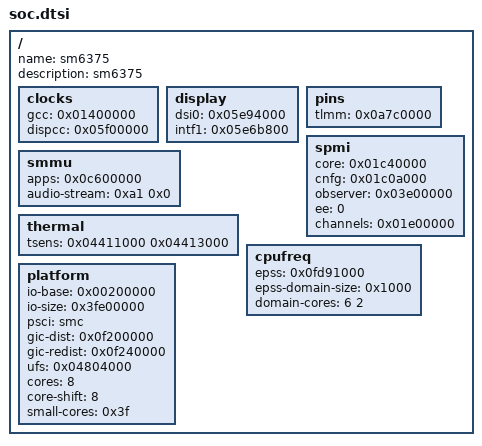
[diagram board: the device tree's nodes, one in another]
/dts-v1/;

// sm6375. Started by tools/boards.py new from malmo.dts.
// What every board with this SoC shares: where its blocks are (Documentation/porting.md).
/ {
	name = "sm6375";
	description = "sm6375";

	// The clocks the display block's registers need before they can be read: for a "dcs" backlight and
	// the feature "display-scan". The addresses are in the tree; the offsets are not -- they are in Linux's
	// clock drivers for the SoC (gcc-CODENAME.c, dispcc-CODENAME.c).
	clocks {
		gcc = <0x01400000>;             // clock-controller@100000 (qcom,CODENAME-gcc); the only key of this section
		                                // that the part drivers need
		// gcc-disp-ahb-cbcr = <0x...>; // TO FILL IN: gcc_disp_ahb_clk: its .halt_reg
		dispcc = <0x05f00000>;          // clock-controller@af00000 (qcom,CODENAME-dispcc)
		// dispcc-mdss-gdscr = <0x...>; // TO FILL IN: the display block's power switch (mdss_core_gdsc): its .gdscr
		// dispcc-mdss-ahb-cbcr = <0x...>; // TO FILL IN: disp_cc_mdss_ahb_clk
	};

	display {
		dsi0 = <0x05e94000>;            // the first DSI controller (cell-index 0), reg "dsi_ctrl"
		intf1 = <0x05e6b800>;           // optional, for "display-scan": the same node's reg "mdp_intf_base"
	};

	// The SoC's own pins (TLMM), for the part drivers that drive them: the touch controllers', the speaker
	// amplifier's, the haptic motor's, the cameras'.
	pins {
		tlmm = <0x0a7c0000>;            // where GPIO 0's registers are; GPIO n's are 0x1000 n further. The pin
		                                // controller's node (qcom,CODENAME-pinctrl): in Linux's trees its reg; in
		                                // the vendor's, whose reg is the whole 16 MiB block, 0x100000 above it
	};

	// The PMIC arbiter (qcom,spmi-pmic-arb), by its reg-names: for the features "buttons-pmic",
	// "torch-pm8350c" and "camera-sm7325".
	spmi {
		core = <0x01c40000>;            // "core"
		cnfg = <0x01c0a000>;            // "cnfg"
		observer = <0x03e00000>;        // "obsrvr": reads
		ee = <0>;                       // qcom,ee; optional, 0 if left out
		channels = <0x01e00000>;        // "chnls": writes; optional, needed only by the drivers that write to a PMIC
	};

	// The SMMU between the SoC's devices and memory, for the part drivers that give a device its addresses
	// (the speakers' audio path, the cameras, Wi-Fi). The GPU's own is in adreno { }.
	smmu {
		apps = <0x0c600000>;            // apps_smmu (the vendor's apps-smmu@15000000; Linux's iommu@15000000)
		audio-stream = <0xa1 0x0>;      // for "speaker-aw88261": the stream the audio DSP reads our samples on,
		                                // ID and mask: the iommus of qcom,msm-audio-ion
	};

	// Temperature, for a board's thermal { }.
	thermal {
		tsens = <0x04411000 0x04413000>; // the TSENS controllers (at most eight), reg "tsens_tm_physical"
	};

	// The cores' frequency hardware, for the feature "cpufreq-epss" and a board's thermal { }: EPSS on the SM8350,
	// SM7325, SC7280 and every chip after them, the OSM's firmware before it (SDM845, SM8150, SM8250, SC7180,
	// SM6350, SM7225). The node is qcom,cpufreq-epss or qcom,cpufreq-hw (the vendor's qcom,cpufreq-hw-epss or
	// qcom,cpufreq-hw); tools/boards.py new --dts reads it, the layout with it.
	cpufreq {
		epss = <0x0fd91000>;            // the first of its "freq-domainN" regs
		epss-domain-size = <0x1000>;    // their size (at least 0x324 for EPSS, 0x924 for the OSM), and the distance
		                                // from one to the next unless domains says otherwise
		domain-cores = <6 2>;           // how many cores each group has, in the cores' order (the cpu@ nodes'
		                                // qcom,freq-domain); one to four groups, together platform { } cores
	};

	// The low-power audio subsystem's blocks on the microphones' path, for the feature "mic-wcd938x". From the
	// SoC's -audio.dtsi (the vendor's). tools/boards.py new finds the addresses and leaves the section commented
	// out, with the SoundWire pins to fill in.
	// lpass {
		// tx-macro = <0x0a620000>;     // tx-macro@3220000 (qcom,tx-macro): the codec macro of the capture side
		// va-macro = <0x0a730000>;     // va-macro@3370000 (qcom,va-macro)
		// tx-swr = <0x...>;            // TO FILL IN: the SoundWire master under the TX macro (qcom,swr-mstr): its reg
		// tx-swr-hctl = <0x...>;       // TO FILL IN: ... and its hardware control register, its qcom,swrm-hctl-reg
		// lpi = <0x0a7c0000>;          // the subsystem's own pins: lpi_pinctrl@33c0000 (qcom,lpi-pinctrl)
		// lpi-slew = <0x0a95a000>;     // ... and that node's qcom,slew-reg
		// swr-tx-pins = <0x...>;       // TO FILL IN: the TX SoundWire master's pins among them, its clock first, then its data
		// swr-tx-slew = <0x...>;       // TO FILL IN: each pin's field in that slew register (the vendor's pinctrl-lpi.c)
	// };

	// What the loader (arch/arm64/boot/) tells the kernel of the machine, for boards with a loader { } section.
	platform {
		io-base = <0x00200000>;
		io-size = <0x3fe00000>;
		psci = "smc";                   // the psci node's method: "smc" or "hvc"
		gic-dist = <0x0f200000>;        // the arm,gic-v3 node's reg: its first entry
		gic-redist = <0x0f240000>;      // ... its second
		ufs = <0x04804000>;             // optional: the UFS host controller (the ufshc node's reg "ufs_mem"), for the
		                                // loader's and the kernel's own requests to the storage (ufs_native=)
		cores = <8>;                    // the cpu@ nodes
		core-shift = <8>;               // where the core's number is in its reg: 8 for 0x000, 0x100 ..., 0 for 0, 1 ...
		small-cores = <0x3f>;           // optional: a bit for each core of the lowest capacity-dmips-mhz
	};
};
